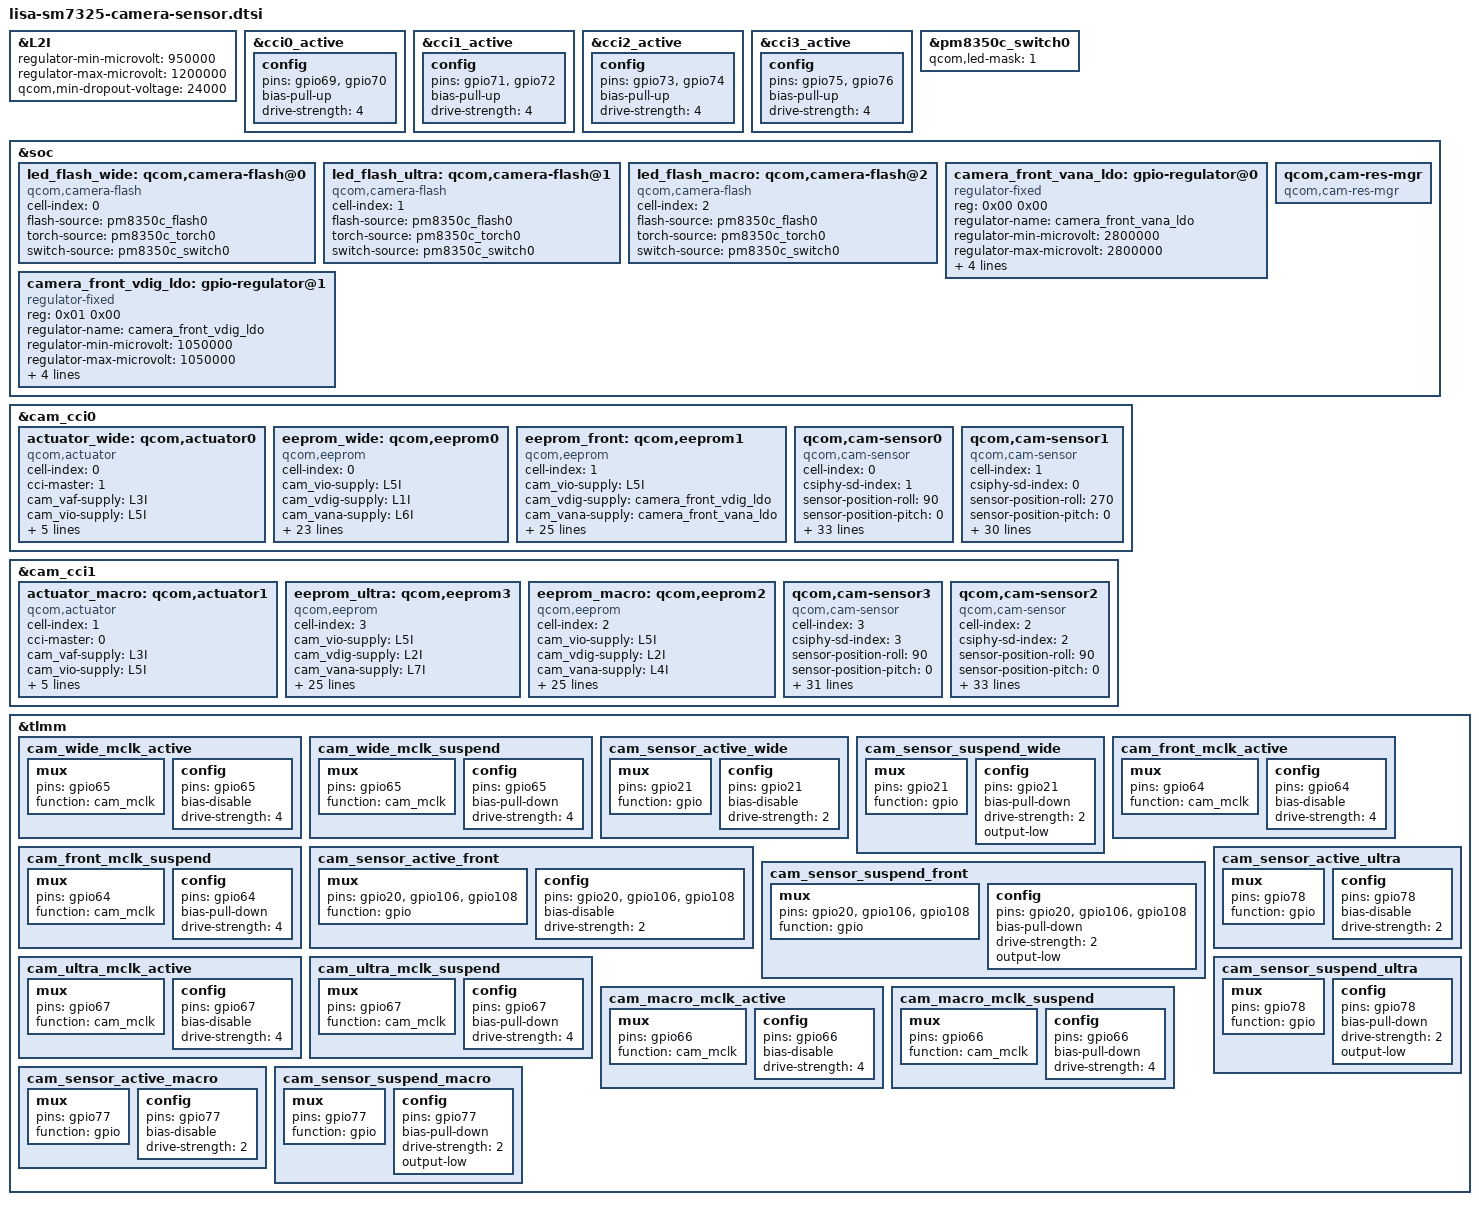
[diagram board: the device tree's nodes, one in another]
#include <dt-bindings/clock/qcom,camcc-yupik.h>


&L2I {
	regulator-min-microvolt = <950000>;
	regulator-max-microvolt = <1200000>;
	qcom,min-dropout-voltage = <24000>;
};



&cci0_active {
	config {
		pins = "gpio69","gpio70";
		bias-pull-up; /* PULL UP*/
		drive-strength = <4>; /* 4 MA */
	};
};

&cci1_active {
	config {
		pins = "gpio71","gpio72";
		bias-pull-up; /* PULL UP*/
		drive-strength = <4>; /* 4 MA */
	};
};

&cci2_active {
	config {
		pins = "gpio73","gpio74";
		bias-pull-up; /* PULL UP*/
		drive-strength = <4>; /* 4 MA */
	};
};

&cci3_active {
	config {
		pins = "gpio75","gpio76";
		bias-pull-up; /* PULL UP*/
		drive-strength = <4>; /* 4 MA */
	};
};

&pm8350c_switch0 {
	qcom,led-mask = <1>; /* Channels 1*/
};

&soc {
	led_flash_wide: qcom,camera-flash@0 {
		cell-index = <0>;
		compatible = "qcom,camera-flash";
		flash-source = <&pm8350c_flash0>;
		torch-source = <&pm8350c_torch0>;
		switch-source = <&pm8350c_switch0>;
		status = "ok";
	};

	led_flash_ultra: qcom,camera-flash@1 {
		cell-index = <1>;
		compatible = "qcom,camera-flash";
		flash-source = <&pm8350c_flash0>;
		torch-source = <&pm8350c_torch0>;
		switch-source = <&pm8350c_switch0>;
		status = "ok";
	};

	led_flash_macro: qcom,camera-flash@2 {
		cell-index = <2>;
		compatible = "qcom,camera-flash";
		flash-source = <&pm8350c_flash0>;
		torch-source = <&pm8350c_torch0>;
		switch-source = <&pm8350c_switch0>;
		status = "ok";
	};

	camera_front_vana_ldo: gpio-regulator@0 {
		compatible = "regulator-fixed";
		reg = <0x00 0x00>;
		regulator-name = "camera_front_vana_ldo";
		regulator-min-microvolt = <2800000>;
		regulator-max-microvolt = <2800000>;
		regulator-enable-ramp-delay = <135>;
		enable-active-high;
		gpio = <&tlmm 106 0>;
		vin-supply = <&BOB>;
	};

	camera_front_vdig_ldo: gpio-regulator@1 {
		compatible = "regulator-fixed";
		reg = <0x01 0x00>;
		regulator-name = "camera_front_vdig_ldo";
		regulator-min-microvolt = <1050000>;
		regulator-max-microvolt = <1050000>;
		regulator-enable-ramp-delay = <135>;
		enable-active-high;
		gpio = <&tlmm 108 0>;
		vin-supply = <&S8B>;
	};

	qcom,cam-res-mgr {
		compatible = "qcom,cam-res-mgr";
	};
};

&cam_cci0 {
	actuator_wide: qcom,actuator0 {
			cell-index = <0>;
			compatible = "qcom,actuator";
			cci-master = <1>;
			cam_vaf-supply = <&L3I>;
			cam_vio-supply = <&L5I>;
			regulator-names = "cam_vaf", "cam_vio";
			rgltr-cntrl-support;
			rgltr-min-voltage = <2800000 1800000>;
			rgltr-max-voltage = <2800000 1800000>;
			rgltr-load-current = <300000 10000>;
			status = "ok";
	};

	eeprom_wide: qcom,eeprom0 {
		cell-index = <0>;
		compatible = "qcom,eeprom";
		cam_vio-supply = <&L5I>;
		cam_vdig-supply = <&L1I>;
		cam_vana-supply = <&L6I>;

		cam_clk-supply = <&cam_cc_titan_top_gdsc>;
		cam_bob-supply = <&BOB>;
		regulator-names = "cam_vio", "cam_vdig", "cam_vana",
			"cam_clk", "cam_bob";
		rgltr-cntrl-support;
		rgltr-min-voltage = <1800000 1056000 2800000 0 3200000>;
		rgltr-max-voltage = <1800000 1056000 2800000 0 3960000>;
		rgltr-load-current = <4800 120000 970000 0 2000000>;
		gpio-no-mux = <0>;
		pinctrl-names = "cam_default", "cam_suspend";
		pinctrl-0 = <&cam_sensor_active_wide>;
		pinctrl-1 = <&cam_sensor_suspend_wide>;
		gpios = <&tlmm 65 0>,
			<&tlmm 21 0>;
		gpio-reset = <1>;
		gpio-req-tbl-num = <0 1>;
		gpio-req-tbl-flags = <1 0>;
		gpio-req-tbl-label = "CAMIF_MCLK1",
					"CAM_RESET1";
		cci-master = <1>;
		clocks = <&camcc CAM_CC_MCLK1_CLK>;
		clock-names = "cam_clk";
		clock-cntl-level = "nominal";
		clock-rates = <19200000>;
		status = "ok";
	};

	eeprom_front: qcom,eeprom1 {
		cell-index = <1>;
		compatible = "qcom,eeprom";
		cam_vio-supply = <&L5I>;
		cam_vdig-supply = <&camera_front_vdig_ldo>;
		cam_vana-supply = <&camera_front_vana_ldo>;
		cam_clk-supply = <&cam_cc_titan_top_gdsc>;
		cam_bob-supply = <&BOB>;
		regulator-names = "cam_vio", "cam_vdig", "cam_vana",
			"cam_clk", "cam_bob";
		rgltr-cntrl-support;
		rgltr-min-voltage = <1800000 1050000 2800000 0 3200000>;
		rgltr-max-voltage = <1800000 1050000 2800000 0 3960000>;
		rgltr-load-current = <10000 140000 280000 0 2000000>;
		gpio-no-mux = <0>;
		pinctrl-names = "cam_default", "cam_suspend";
		pinctrl-0 = <&cam_sensor_active_front
			&cam_front_mclk_active>;
		pinctrl-1 = <&cam_sensor_suspend_front
			&cam_front_mclk_suspend>;
		gpios = <&tlmm 64 0>,
			<&tlmm 20 0>;
		gpio-reset = <1>;
		gpio-req-tbl-num = <0 1>;
		gpio-req-tbl-flags = <1 0>;
		gpio-req-tbl-label = "CAMIF_MCLK0",
					"CAM_RESET0";
		cci-master = <0>;
		clocks = <&camcc CAM_CC_MCLK0_CLK>;
		clock-names = "cam_clk";
		clock-cntl-level = "nominal";
		clock-rates = <19200000>;
		status = "ok";
	};


	// wide S5KGW3 64M (AVDD 2.8V ) (VIO 1.8) (DVDD 1.05 )
	qcom,cam-sensor0 {
		cell-index = <0>;
		compatible = "qcom,cam-sensor";
		csiphy-sd-index = <1>;
		sensor-position-roll = <90>;
		sensor-position-pitch = <0>;
		sensor-position-yaw = <180>;
		eeprom-src = <&eeprom_wide>;
		actuator-src = <&actuator_wide>;
		led-flash-src = <&led_flash_wide>;

		cam_vio-supply = <&L5I>;
		cam_vdig-supply = <&L1I>;
		cam_vana-supply = <&L6I>;
		cam_vaf_supply = <&L3I>;

		cam_clk-supply = <&cam_cc_titan_top_gdsc>;
		cam_bob-supply = <&BOB>;
		regulator-names = "cam_vio", "cam_vdig", "cam_vana", "cam_vaf", "cam_clk", "cam_bob";
		rgltr-cntrl-support;
		rgltr-min-voltage = <1800000 1056000 2800000 2800000 0 3200000>;
		rgltr-max-voltage = <1800000 1056000 2800000 2800000 0 3960000>;
		rgltr-load-current = <4800 120000 970000 106000 0 2000000>;
		gpio-no-mux = <0>;
                pinctrl-names = "cam_default", "cam_suspend";
                pinctrl-0 = <&cam_sensor_active_wide
                        &cam_wide_mclk_active>;
                pinctrl-1 = <&cam_sensor_suspend_wide
                        &cam_wide_mclk_suspend>;
		gpios = <&tlmm 65 0>,
			<&tlmm 21 0>;
		gpio-reset = <1>;
		gpio-req-tbl-num = <0 1>;
		gpio-req-tbl-flags = <1 0>;
		gpio-req-tbl-label = "CAMIF_MCLK1",
					"CAM_RESET1";
		cci-master = <1>;
		clocks = <&camcc CAM_CC_MCLK1_CLK>;
		clock-names = "cam_clk";
		clock-cntl-level = "nominal";
		clock-rates = <19200000>;
		status = "ok";
	};

	// Front OV16A1Q (AVDD 2.8V )  (VIO 1.8) (DVDD 1.05 )
	qcom,cam-sensor1 {
		cell-index = <1>;
		compatible = "qcom,cam-sensor";
		csiphy-sd-index = <0>;
		sensor-position-roll = <270>;
		sensor-position-pitch = <0>;
		sensor-position-yaw = <0>;
		eeprom-src = <&eeprom_front>;
		cam_vio-supply = <&L5I>;
		cam_vdig-supply = <&camera_front_vdig_ldo>;
		cam_vana-supply = <&camera_front_vana_ldo>;
		cam_clk-supply = <&cam_cc_titan_top_gdsc>;
		cam_bob-supply = <&BOB>;
		regulator-names = "cam_vio", "cam_vdig", "cam_vana",
			"cam_clk", "cam_bob";
		rgltr-cntrl-support;
		rgltr-min-voltage = <1800000 1050000 2800000 0 3200000>;
		rgltr-max-voltage = <1800000 1050000 2800000 0 3960000>;
		rgltr-load-current = <10000 140000 280000 0 2000000>;
		gpio-no-mux = <0>;
		pinctrl-names = "cam_default", "cam_suspend";
		pinctrl-0 = <&cam_sensor_active_front
			&cam_front_mclk_active>;
		pinctrl-1 = <&cam_sensor_suspend_front
			&cam_front_mclk_suspend>;
		gpios = <&tlmm 64 0>,
			<&tlmm 20 0>;
		gpio-reset = <1>;
		gpio-req-tbl-num = <0 1>;
		gpio-req-tbl-flags = <1 0>;
		gpio-req-tbl-label = "CAMIF_MCLK0",
					"CAM_RESET0";
		cci-master = <0>;
		clocks = <&camcc CAM_CC_MCLK0_CLK>;
		clock-names = "cam_clk";
		clock-cntl-level = "nominal";
		clock-rates = <19200000>;
		status = "ok";
	};

};

&cam_cci1 {
	actuator_macro: qcom,actuator1 {
		cell-index = <1>;
		compatible = "qcom,actuator";
		cci-master = <0>;
		cam_vaf-supply = <&L3I>;
		cam_vio-supply = <&L5I>;
		regulator-names = "cam_vaf", "cam_vio";
		rgltr-cntrl-support;
		rgltr-min-voltage = <2800000 1800000>;
		rgltr-max-voltage = <2800000 1800000>;
		rgltr-load-current = <300000 10000>;
		status = "ok";
	};

	eeprom_ultra: qcom,eeprom3 {
		cell-index = <3>;
		compatible = "qcom,eeprom";
		cam_vio-supply = <&L5I>;
		cam_vdig-supply = <&L2I>;
		cam_vana-supply = <&L7I>;
		cam_clk-supply = <&cam_cc_titan_top_gdsc>;
		cam_bob-supply = <&BOB>;
		regulator-names = "cam_vio", "cam_vdig", "cam_vana"
			,"cam_clk", "cam_bob";
		rgltr-cntrl-support;
		rgltr-min-voltage = <1800000 1200000 2704000 0 3200000>;
		rgltr-max-voltage = <1800000 1200000 2704000 0 3960000>;
		rgltr-load-current = <10000 140000 180000 0 2000000>;
		gpio-no-mux = <0>;
		pinctrl-names = "cam_default", "cam_suspend";
		pinctrl-0 = <&cam_sensor_active_ultra
				&cam_ultra_mclk_active>;
		pinctrl-1 = <&cam_sensor_suspend_ultra
				&cam_ultra_mclk_suspend>;
		gpios = <&tlmm 67 0>,
			<&tlmm 78 0>;
		gpio-reset = <1>;
		gpio-req-tbl-num = <0 1>;
		gpio-req-tbl-flags = <1 0>;
		gpio-req-tbl-label = "CAMIF_MCLK3",
					"CAM_RESET3";
		cci-master = <1>;
		clocks = <&camcc CAM_CC_MCLK3_CLK>;
		clock-names = "cam_clk";
		clock-cntl-level = "nominal";
		clock-rates = <19200000>;
		status = "ok";
	};

	eeprom_macro: qcom,eeprom2 {
		cell-index = <2>;
		compatible = "qcom,eeprom";
		cam_vio-supply = <&L5I>;
		cam_vdig-supply = <&L2I>;
		cam_vana-supply = <&L4I>;
		cam_clk-supply = <&cam_cc_titan_top_gdsc>;
		cam_bob-supply = <&BOB>;
		regulator-names = "cam_vio", "cam_vdig", "cam_vana"
			          , "cam_clk", "cam_bob";
		rgltr-cntrl-support;
		rgltr-min-voltage = <1800000 1200000 2800000 0 3200000>;
		rgltr-max-voltage = <1800000 1200000 2800000 0 3960000>;
		rgltr-load-current = <10000 140000 180000 0 2000000>;
		gpio-no-mux = <0>;
		pinctrl-names = "cam_default", "cam_suspend";
		pinctrl-0 = <&cam_sensor_active_macro
				&cam_macro_mclk_active>;
		pinctrl-1 = <&cam_sensor_suspend_macro
				&cam_macro_mclk_suspend>;
		gpios = <&tlmm 66 0>,
			<&tlmm 77 0>;
		gpio-reset = <1>;
		gpio-req-tbl-num = <0 1>;
		gpio-req-tbl-flags = <1 0>;
		gpio-req-tbl-label = "CAMIF_MCLK2",
					"CAM_RESET2";
		cci-master = <0>;
		clocks = <&camcc CAM_CC_MCLK2_CLK>;
		clock-names = "cam_clk";
		clock-cntl-level = "nominal";
		clock-rates = <19200000>;
		status = "ok";
	};

	// Ultra IMX355 (AVDD 2.7V )  (VIO 1.8) (DVDD 1.2 )
	qcom,cam-sensor3 {
		cell-index = <3>;
		compatible = "qcom,cam-sensor";
		csiphy-sd-index = <3>;
		sensor-position-roll = <90>;
		sensor-position-pitch = <0>;
		sensor-position-yaw = <180>;
		eeprom-src = <&eeprom_ultra>;
		led-flash-src = <&led_flash_ultra>;
		cam_vio-supply = <&L5I>;
		cam_vdig-supply = <&L2I>;
		cam_vana-supply = <&L7I>;
		cam_clk-supply = <&cam_cc_titan_top_gdsc>;
		cam_bob-supply = <&BOB>;
		regulator-names = "cam_vio", "cam_vdig", "cam_vana"
			,"cam_clk", "cam_bob";
		rgltr-cntrl-support;
		rgltr-min-voltage = <1800000 1200000 2704000 0 3200000>;
		rgltr-max-voltage = <1800000 1200000 2704000 0 3960000>;
		rgltr-load-current = <10000 140000 180000 0 2000000>;
		gpio-no-mux = <0>;
		pinctrl-names = "cam_default", "cam_suspend";
		pinctrl-0 = <&cam_sensor_active_ultra
				&cam_ultra_mclk_active>;
		pinctrl-1 = <&cam_sensor_suspend_ultra
				&cam_ultra_mclk_suspend>;
		gpios = <&tlmm 67 0>,
			<&tlmm 78 0>;
		gpio-reset = <1>;
		gpio-req-tbl-num = <0 1>;
		gpio-req-tbl-flags = <1 0>;
		gpio-req-tbl-label = "CAMIF_MCLK3",
					"CAM_RESET3";
		cci-master = <1>;
		clocks = <&camcc CAM_CC_MCLK3_CLK>;
		clock-names = "cam_clk";
		clock-cntl-level = "nominal";
		clock-rates = <19200000>;
		status = "ok";
	};

	// MACRO S5K5E9  (AVDD 2.8V )  (VIO 1.8) (DVDD 1.2 )
	qcom,cam-sensor2 {
		cell-index = <2>;
		compatible = "qcom,cam-sensor";
		csiphy-sd-index = <2>;
		sensor-position-roll = <90>;
		sensor-position-pitch = <0>;
		sensor-position-yaw = <180>;
		eeprom-src = <&eeprom_macro>;
		led-flash-src = <&led_flash_macro>;
		actuator-src = <&actuator_macro>;
		cam_vio-supply = <&L5I>;
		cam_vdig-supply = <&L2I>;
		cam_vana-supply = <&L4I>;
		cam_vaf-supply = <&L3I>;
		cam_clk-supply = <&cam_cc_titan_top_gdsc>;
		cam_bob-supply = <&BOB>;
		regulator-names = "cam_vio", "cam_vdig", "cam_vana", "cam_vaf"
			          , "cam_clk", "cam_bob";
		rgltr-cntrl-support;
		rgltr-min-voltage = <1800000 1200000 2800000 2800000 0 3200000>;
		rgltr-max-voltage = <1800000 1200000 2800000 2800000 0 3960000>;
		rgltr-load-current = <10000 140000 180000 296000 0 2000000>;
		gpio-no-mux = <0>;
		pinctrl-names = "cam_default", "cam_suspend";
		pinctrl-0 = <&cam_sensor_active_macro
				&cam_macro_mclk_active>;
		pinctrl-1 = <&cam_sensor_suspend_macro
				&cam_macro_mclk_suspend>;
		gpios = <&tlmm 66 0>,
			<&tlmm 77 0>;
		gpio-reset = <1>;
		gpio-req-tbl-num = <0 1>;
		gpio-req-tbl-flags = <1 0>;
		gpio-req-tbl-label = "CAMIF_MCLK2",
					"CAM_RESET2";
		cci-master = <0>;
		clocks = <&camcc CAM_CC_MCLK2_CLK>;
		clock-names = "cam_clk";
		clock-cntl-level = "nominal";
		clock-rates = <19200000>;
		status = "ok";
	};
};

&tlmm {
	cam_wide_mclk_active: cam_wide_mclk_active {
		mux {
				pins = "gpio65";
				function = "cam_mclk";
			};

		config {
				pins = "gpio65";
				bias-disable; /* No PULL */
				drive-strength = <4>; /* 4 MA */
		};
	};

	cam_wide_mclk_suspend: cam_wide_mclk_suspend {
		mux {
				pins = "gpio65";
				function = "cam_mclk";
		};

		config {
				pins = "gpio65";
				bias-pull-down; /* PULL DOWN */
				drive-strength = <4>; /* 4 MA */
		};
	};

	cam_sensor_active_wide: cam_sensor_active_wide {
		mux {
			pins = "gpio21";
			function = "gpio";
		};

		config {
			pins = "gpio21";
			bias-disable; /* No PULL */
			drive-strength = <2>; /* 2 MA */
		};
	};

	cam_sensor_suspend_wide: cam_sensor_suspend_wide {
		mux {
			pins = "gpio21";
			function = "gpio";
		};

		config {
			pins = "gpio21";
			bias-pull-down; /* PULL DOWN */
			drive-strength = <2>; /* 2 MA */
			output-low;
		};
	};

	cam_front_mclk_active: cam_front_mclk_active {
		mux {
			pins = "gpio64";
			function = "cam_mclk";
		};

		config {
			pins = "gpio64";
			bias-disable; /* No PULL */
			drive-strength = <4>; /* 4 MA */
		};
	};

	cam_front_mclk_suspend: cam_front_mclk_suspend {
		mux {
			pins = "gpio64";
			function = "cam_mclk";
		};

		config {
			pins = "gpio64";
			bias-pull-down; /* PULL DOWN */
			drive-strength = <4>; /* 4 MA */
		};
	};

	cam_sensor_active_front: cam_sensor_active_front {
		/*RESET AVDD DVDD*/
		mux {
			pins = "gpio20", "gpio106", "gpio108";
			function = "gpio";
		};

		config {
			pins = "gpio20", "gpio106", "gpio108";
			bias-disable; /* No PULL */
			drive-strength = <2>; /* 2 MA */
		};
	};

	cam_sensor_suspend_front: cam_sensor_suspend_front {
		mux {
			pins = "gpio20", "gpio106", "gpio108";
			function = "gpio";
		};

		config {
			pins = "gpio20", "gpio106", "gpio108";
			bias-pull-down; /* PULL DOWN */
			drive-strength = <2>; /* 2 MA */
			output-low;
		};
	};

	cam_ultra_mclk_active: cam_ultra_mclk_active {
		mux {
			pins = "gpio67";
			function = "cam_mclk";
		};

		config {
			pins = "gpio67";
			bias-disable; /* No PULL */
			drive-strength = <4>; /* 4 MA */
		};
	};

	cam_ultra_mclk_suspend: cam_ultra_mclk_suspend {
		mux {
			pins = "gpio67";
			function = "cam_mclk";
		};

		config {
			pins = "gpio67";
			bias-pull-down; /* PULL DOWN */
			drive-strength = <4>; /* 4 MA */
		};
	};

	cam_sensor_active_ultra: cam_sensor_active_ultra {
		/*RESET */
		mux {
			pins = "gpio78";
			function = "gpio";
		};

		config {
			pins = "gpio78";
			bias-disable; /* No PULL */
			drive-strength = <2>; /* 2 MA */
		};
	};

	cam_sensor_suspend_ultra: cam_sensor_suspend_ultra {
		mux {
			pins = "gpio78";
			function = "gpio";
		};

		config {
			pins = "gpio78";
			bias-pull-down; /* PULL DOWN */
			drive-strength = <2>; /* 2 MA */
			output-low;
		};
	};

	cam_macro_mclk_active: cam_macro_mclk_active {
		mux {
			pins = "gpio66";
			function = "cam_mclk";
		};

		config {
			pins = "gpio66";
			bias-disable; /* No PULL */
			drive-strength = <4>; /* 2 MA */
		};
	};

	cam_macro_mclk_suspend: cam_macro_mclk_suspend {
		mux {
			pins = "gpio66";
			function = "cam_mclk";
		};

		config {
			pins = "gpio66";
			bias-pull-down; /* PULL DOWN */
			drive-strength = <4>; /* 2 MA */
		};
	};

	cam_sensor_active_macro: cam_sensor_active_macro {
		/*RESET */
		mux {
			pins = "gpio77";
			function = "gpio";
		};

		config {
			pins = "gpio77";
			bias-disable; /* No PULL */
			drive-strength = <2>; /* 2 MA */
		};
	};

	cam_sensor_suspend_macro: cam_sensor_suspend_macro {
		mux {
			pins = "gpio77";
			function = "gpio";
		};

		config {
			pins = "gpio77";
			bias-pull-down; /* PULL DOWN */
			drive-strength = <2>; /* 2 MA */
			output-low;
		};
	};
};
